# M55M1 register map
File version: 1.0
Registers are 32-bit, read-write, reset 0x0 unless marked. A register's access mark holds for its fields unless they carry their own. Offsets are from the block's base; [hi:lo] are bit positions; {n}, {i} and the like mark numbered series; 'fields as' and 'values as' point back to an identical list.

## DMIC_NS — DMIC Register Map
Base 0x50445000
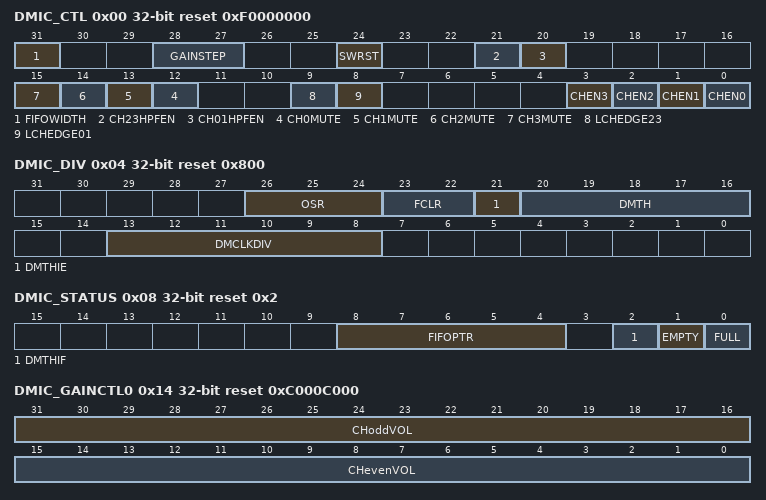
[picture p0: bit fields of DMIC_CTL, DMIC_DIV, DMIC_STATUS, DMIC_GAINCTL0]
0x00 DMIC_CTL reset 0xF0000000 — DMIC Control Register
  [31] FIFOWIDTH — Data Effective Bit in FIFO
    0=16-bit, Data Truncated LSB bit0~bit7. [15:0]; 1=24-bit
  [28:27] GAINSTEP — Volume Control Gain Adjust Step for Decimal Point
    0=0.5dB (1/2); 1=0.25dB (1/4); 2=0.125dB (1/8); 3=0.0625dB (1/16)
  [24] SWRST — Internal State Software Reset. Set this bit to 1 to Reset DMIC state machine, but all DMIC registers are kept unchanged.
    0=Normal operation; 1=DMIC State Machine Reset
  [21] CH23HPFEN — DMIC Channel 23 HPF filter Enable. Set this bit to 1 to Enable DMIC channel 2 and channel 3 HPF filter for remove DC component.
    0=DMIC Channel 23 HPF Disabled; 1=DMIC Channel 23 HPF Enabled
  [20] CH01HPFEN — DMIC Channel 01 HPF filter Enable. Set this bit to 1 to Enable DMIC channel 0 and channel 1 HPF filter for remove DC component.
    0=DMIC Channel 01 HPF Disabled; 1=DMIC Channel 01 HPF Enabled
  [n+12] CH{n}MUTE (n=0..3) — DMIC Channel {n} Mute Enable. Set this bit to 1 to mute DMIC channel {n}.
    0=DMIC Channel {n} Unmute; 1=DMIC Channel {n} Mute
  [9] LCHEDGE23 — DMIC Channel 23 Data Latch Edge. The data of DMIC channel 2 and channel 3 is latched on DMIC1_DAT pin. This bit is used to select the data of DMIC channel 2 and channel 3 is latched on rising or falling edge of DMIC1_CLK (DMIC bus clock).
    0=The data of channel 2 is latched on falling edge of DMIC1_CLK. The data of channel 3 is latched on rising edge of DMIC1_CLK; 1=The data of channel 2 is latched on rising edge of DMIC1_CLK. The data of channel 3 is latched on falling edge of DMIC1_CLK
  [8] LCHEDGE01 — DMIC Channel 01 Data Latch Edge. The data of DMIC channel 0 and channel 1 is latched on DMIC0_DAT pin. This bit is used to select the data of DMIC channel 0 and channel 1 is latched on rising or falling edge of DMIC0_CLK and DMIC0_CLKLP(DMIC bus clock).
    0=The data of channel 0 is latched on falling edge of DMIC0_CLKLP. The data of channel 1 is latched on rising edge of DMIC0_CLK; 1=The data of channel 0 is latched on rising edge of DMIC0_CLKLP. The data of channel 1 is latched on falling edge of DMIC0_CLK
  [n] CHEN{n} (n=0..3) — DMIC Channel {n} Enable. Set this bit to 1 to enable DMIC channel {n} operation.
    0=DMIC Channel {n} Disabled; 1=DMIC Channel {n} Enabled
0x04 DMIC_DIV reset 0x800 — DMIC Clock Divider Register
  [26:24] OSR — DMIC OSR Setting
    0=Down sample 64; 1=Down sample 128; 2=Down sample 256; 3=Down sample 100; 7=Down sample 50
  [23:22] FCLR — FIFO Clear. Note 1: To clear the FIFO, need to write FCLR (DMIC_DIV[23:22]) to 11b, and can read the EMPTY (DMIC_STATUS[1]) bit to make sure that the FIFO has been cleared. Note 2: This field is auto cleared by hardware.
    3=Clear the FIFO
  [21] DMTHIE — FIFO Threshold Interrupt
    0=FIFO threshold interrupt and DMTHIF (DMIC_STATUS[2]) flag Disabled; 1=FIFO threshold interrupt and DMTHIF (DMIC_STATUS[2]) flag Enabled
  [20:16] DMTH — FIFO Threshold Level. If the valid data count of the FIFO data buffer is more than or equal to DMTH (DMIC_DIV[20:16]) setting, the DMTHIF (DMIC_STATUS[2]) bit will set to 1, else the DMTHIF (DMIC_STATUS[2]) bit will be cleared to 0.
  [13:8] DMCLKDIV — Divider to generate the DMIC Bus Clock. The value in this field is the frequency divider for generating the DMIC bus clock. The frequency is obtained according to the following equation. where F_DMIC_MCLK is the frequency of DMIC working main clock (DMIC_MCLK) and F_DMIC_CLK is the frequency of DMIC bus clock (DMIC_CLK).
0x08 DMIC_STATUS ro reset 0x2
  [8:4] FIFOPTR — FIFO Pointer (Read Only). The FULL (DMIC_STATUS[0]) and FIFOPTR (DMIC_STATUS[8:4]) indicates the field that the valid data count within the DMIC FIFO buffer. The maximum value shown in FIFOPTR (DMIC_STATUS[8:4]) is 31. When the using level of DMIC FIFO buffer equal to 32, The FULL (DMIC_STATUS[0]) is set to 1.
  [2] DMTHIF — FIFO Threshold Interrupt Status (Read Only)
    0=The valid data count within the FIFO data buffer is less than the setting value of DMTH (DMIC_DIV[20:16]) or (DMIC_DIV[21])=0; 1=The valid data count within the FIFO data buffer is more than or equal to the setting value of TH (DMIC_DIV[20:16]) and (DMIC_DIV[21])=1
  [1] EMPTY — FIFO Empty Indicator (Read Only)
    0=FIFO is not empty; 1=FIFO is empty
  [0] FULL — FIFO Full Indicator (Read Only)
    0=FIFO is not full; 1=FIFO is full
0x0C DMIC_LPPDMACTL — DMIC LPPDMA Control Register
  [0] LPPDMAEN — LPPDMA Transfer Enable Bit. If through set CHANx(DMIC_CTL[3:0]) enalble in CPU to active DMIC mode, only this bit can enable LPPDMA.
    0=LPPDMA data transfer Disabled.PCM Data can be read from the FIFO Data Output Register by the CPU; 1=LPPDMA data transfer Enabled
0x10 DMIC_FIFO ro — DMIC FIFO Data Output Register
  [23:0] FIFO — FIFO Data Output Register. DMIC contains 32 level (32x24 bit) data buffer for data receive. A read to this register pushes data out from FIFO data buffer and decrements the read pointer. This is the address that LPPDMA reads audio data from. The remaining data word number is indicated by FIFOPTR (DMIC_STATUS[8:4]).
0x14 DMIC_GAINCTL0 reset 0xC000C000 — DMIC Channel 0 and 1 Volume Control Register
  [31:16] CHoddVOL — Channel Odd Volume/Gain Control, 0.125dB Step. Channel odd volume/gain control CHoddVOL, in 9 intergers + 4 fractional bits. DMIC_GAINCTLx[31] and DMIC_GAINCTLx [16] correspond to MSB and LSB respectively.
  [15:0] CHevenVOL — Channel Even Volume/Gain Control, 0.125dB Step. Channel even volume/gain control CHevenVOL, in 9 intergers + 4 fractional bits. DMIC_GAINCTLx[15] and DMIC_GAINCTLx [0] correspond to MSB and LSB respectively
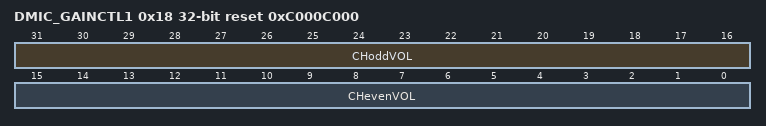
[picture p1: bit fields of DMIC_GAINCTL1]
0x18 DMIC_GAINCTL1 reset 0xC000C000 — DMIC Channel 2 and 3 Volume Control Register
  fields as DMIC_GAINCTL0
